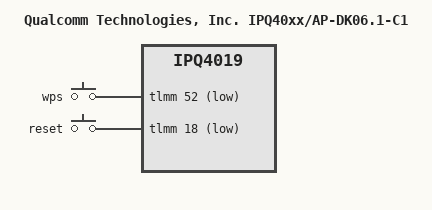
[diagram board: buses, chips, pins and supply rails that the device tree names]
/* Copyright (c) 2016, The Linux Foundation. All rights reserved.
 *
 * Permission to use, copy, modify, and/or distribute this software for any
 * purpose with or without fee is hereby granted, provided that the above
 * copyright notice and this permission notice appear in all copies.
 *
 * THE SOFTWARE IS PROVIDED "AS IS" AND THE AUTHOR DISCLAIMS ALL WARRANTIES
 * WITH REGARD TO THIS SOFTWARE INCLUDING ALL IMPLIED WARRANTIES OF
 * MERCHANTABILITY AND FITNESS. IN NO EVENT SHALL THE AUTHOR BE LIABLE FOR
 * ANY SPECIAL, DIRECT, INDIRECT, OR CONSEQUENTIAL DAMAGES OR ANY DAMAGES
 * WHATSOEVER RESULTING FROM LOSS OF USE, DATA OR PROFITS, WHETHER IN AN
 * ACTION OF CONTRACT, NEGLIGENCE OR OTHER TORTIOUS ACTION, ARISING OUT OF
 * OR IN CONNECTION WITH THE USE OR PERFORMANCE OF THIS SOFTWARE.
 *
 */
#include "qcom-ipq4019-ap.dk04.1.dtsi"
/{
	model = "Qualcomm Technologies, Inc. IPQ40xx/AP-DK06.1-C1";
	soc {

		sdhc_1: sdhci@7824000 {
			status = "disabled";
		};

		qcom,Gobi {
			compatible = "qcom,gobi-9x35";
			status = "ok";
		};

		qcom: ledc@1937000  {
			qcom,tcsr_ledc_values = <0x320193 0x1A72004A 0x10 0x0 \
				0x0 0xFFFFFFFF 0x80 0x6 0x7D0010 \
				0x0 0x10482090 0x3FFFDFC>;
		};

		gpio_keys {
			compatible = "gpio-keys";
			button@1 {
				label = "wps";
				linux,code = <KEY_WPS_BUTTON>;
				gpios = <&tlmm 52 GPIO_ACTIVE_LOW>;
				linux,input-type = <1>;
			};
			button@2 {
				label = "reset";
				linux,code = <KEY_RESTART>;
				gpios = <&tlmm 18 GPIO_ACTIVE_LOW>;
				linux,input-type = <1>;
			};
		};
	};
};
